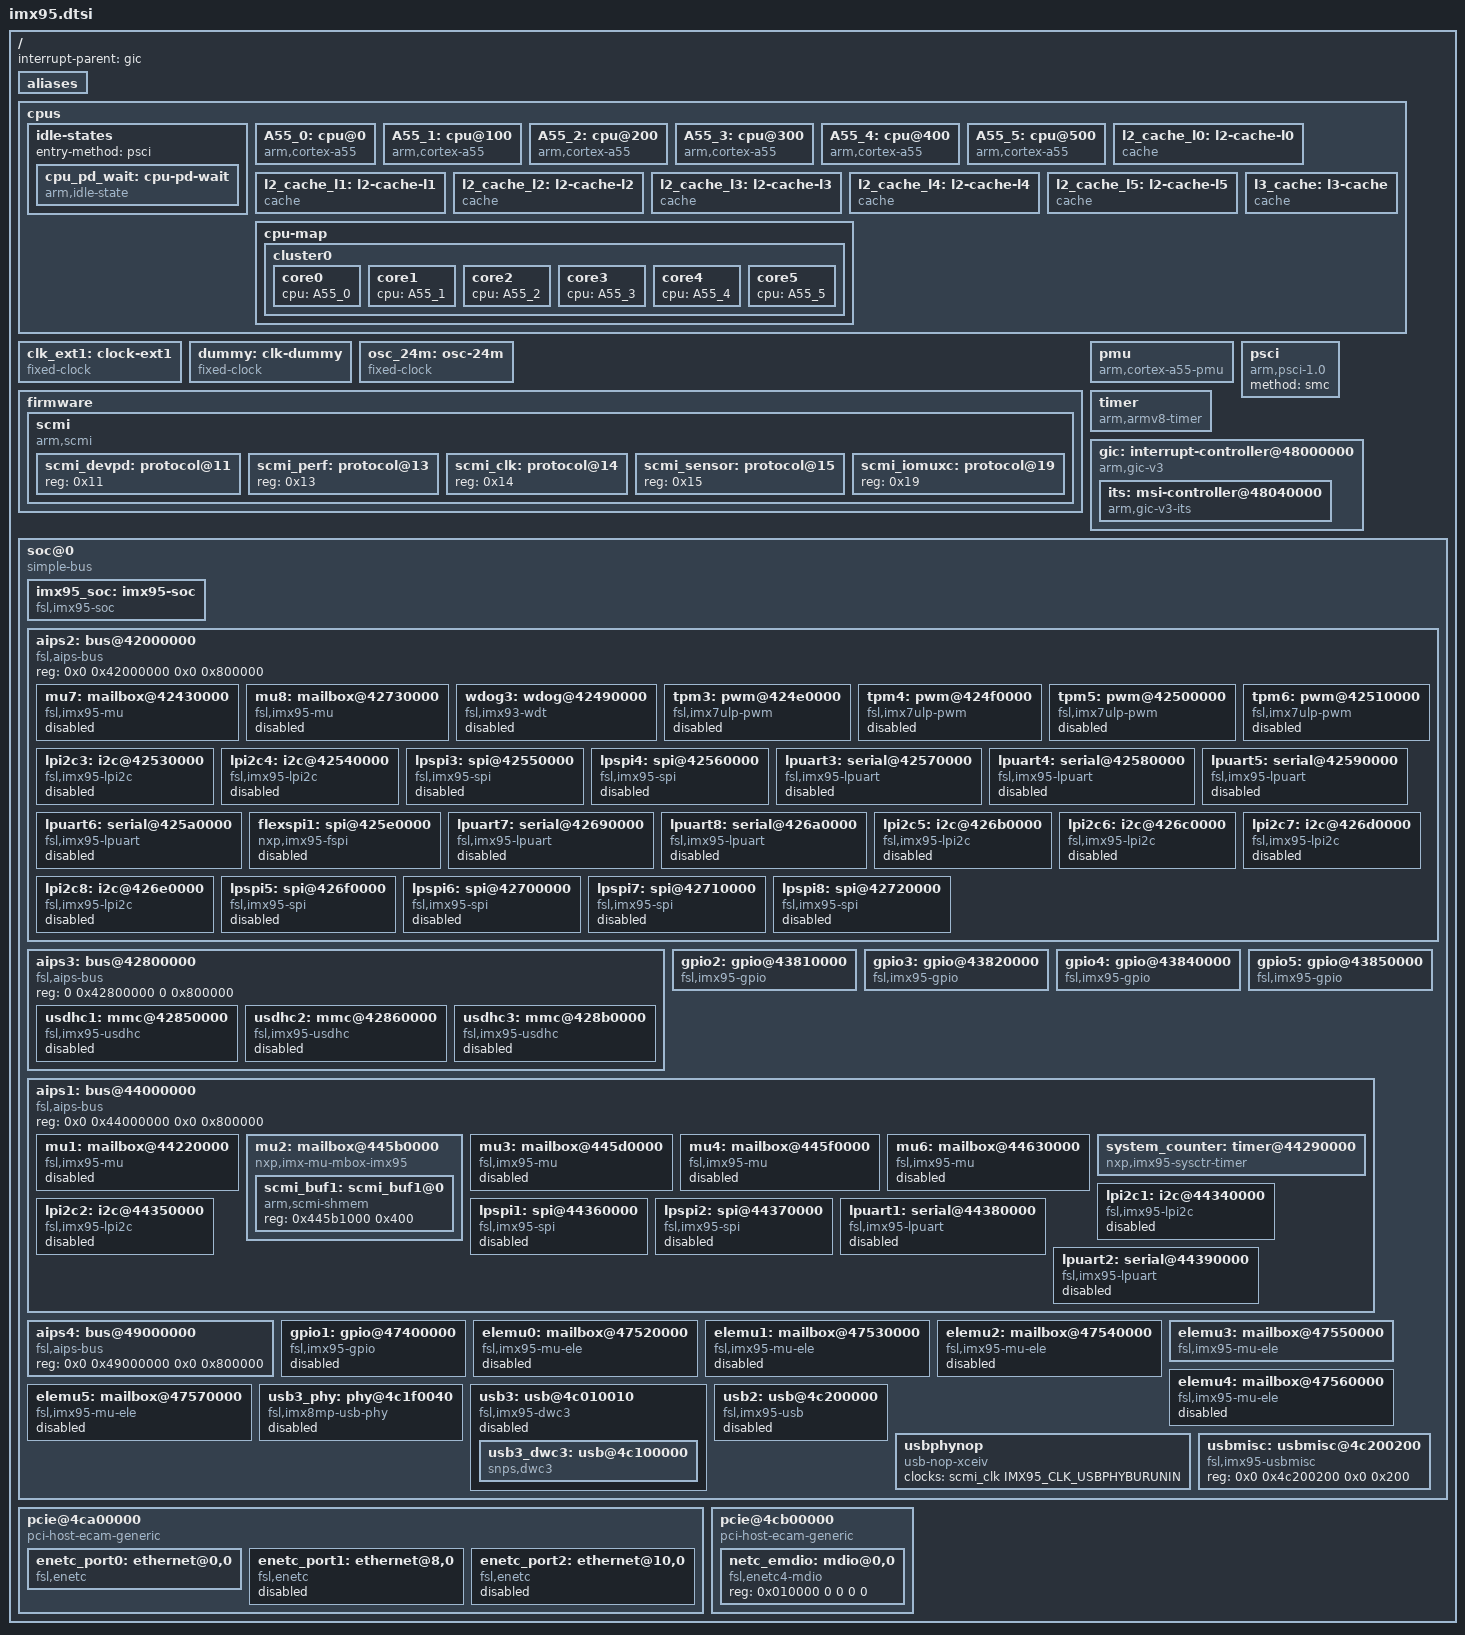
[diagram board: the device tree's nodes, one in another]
// SPDX-License-Identifier: (GPL-2.0+ OR MIT)
/*
 * Copyright 2023 NXP
 */

#include <dt-bindings/clock/fsl,imx95-clock.h>
#include <dt-bindings/gpio/gpio.h>
#include <dt-bindings/input/input.h>
#include <dt-bindings/interrupt-controller/arm-gic.h>
#include <dt-bindings/power/fsl,imx95-power.h>

#include "imx95-pinfunc.h"

/ {
	interrupt-parent = <&gic>;
	#address-cells = <2>;
	#size-cells = <2>;

	aliases {
		gpio0 = &gpio1;
		gpio1 = &gpio2;
		gpio2 = &gpio3;
		gpio3 = &gpio4;
		gpio4 = &gpio5;
		i2c0 = &lpi2c1;
		i2c1 = &lpi2c2;
		i2c2 = &lpi2c3;
		i2c3 = &lpi2c4;
		i2c4 = &lpi2c5;
		i2c5 = &lpi2c6;
		i2c6 = &lpi2c7;
		i2c7 = &lpi2c8;
		mmc0 = &usdhc1;
		mmc1 = &usdhc2;
		mmc2 = &usdhc3;
		serial0 = &lpuart1;
		serial1 = &lpuart2;
		serial2 = &lpuart3;
		serial3 = &lpuart4;
		serial4 = &lpuart5;
		serial5 = &lpuart6;
		serial6 = &lpuart7;
		serial7 = &lpuart8;
		spi0 = &flexspi1;
		usb0 = &usb3_dwc3;
		usb1 = &usb2;
	};

	cpus {
		#address-cells = <1>;
		#size-cells = <0>;

		idle-states {
			entry-method = "psci";

			cpu_pd_wait: cpu-pd-wait {
				compatible = "arm,idle-state";
				arm,psci-suspend-param = <0x0010033>;
				local-timer-stop;
				entry-latency-us = <1000>;
				exit-latency-us = <700>;
				min-residency-us = <2700>;
				wakeup-latency-us = <1500>;
			};
		};

		A55_0: cpu@0 {
			device_type = "cpu";
			compatible = "arm,cortex-a55";
			reg = <0x0>;
			enable-method = "psci";
			#cooling-cells = <2>;
			cpu-idle-states = <&cpu_pd_wait>;
			power-domains = <&scmi_devpd IMX95_PERF_A55>;
			power-domain-names = "perf";
			i-cache-size = <32768>;
			i-cache-line-size = <64>;
			i-cache-sets = <128>;
			d-cache-size = <32768>;
			d-cache-line-size = <64>;
			d-cache-sets = <128>;
			next-level-cache = <&l2_cache_l0>;
		};

		A55_1: cpu@100 {
			device_type = "cpu";
			compatible = "arm,cortex-a55";
			reg = <0x100>;
			enable-method = "psci";
			#cooling-cells = <2>;
			cpu-idle-states = <&cpu_pd_wait>;
			power-domains = <&scmi_devpd IMX95_PERF_A55>;
			power-domain-names = "perf";
			i-cache-size = <32768>;
			i-cache-line-size = <64>;
			i-cache-sets = <128>;
			d-cache-size = <32768>;
			d-cache-line-size = <64>;
			d-cache-sets = <128>;
			next-level-cache = <&l2_cache_l1>;
		};

		A55_2: cpu@200 {
			device_type = "cpu";
			compatible = "arm,cortex-a55";
			reg = <0x200>;
			enable-method = "psci";
			#cooling-cells = <2>;
			cpu-idle-states = <&cpu_pd_wait>;
			power-domains = <&scmi_devpd IMX95_PERF_A55>;
			power-domain-names = "perf";
			i-cache-size = <32768>;
			i-cache-line-size = <64>;
			i-cache-sets = <128>;
			d-cache-size = <32768>;
			d-cache-line-size = <64>;
			d-cache-sets = <128>;
			next-level-cache = <&l2_cache_l2>;
		};

		A55_3: cpu@300 {
			device_type = "cpu";
			compatible = "arm,cortex-a55";
			reg = <0x300>;
			enable-method = "psci";
			#cooling-cells = <2>;
			power-domains = <&scmi_devpd IMX95_PERF_A55>;
			power-domain-names = "perf";
			i-cache-size = <32768>;
			i-cache-line-size = <64>;
			i-cache-sets = <128>;
			d-cache-size = <32768>;
			d-cache-line-size = <64>;
			d-cache-sets = <128>;
			next-level-cache = <&l2_cache_l3>;
		};

		A55_4: cpu@400 {
			device_type = "cpu";
			compatible = "arm,cortex-a55";
			reg = <0x400>;
			power-domains = <&scmi_devpd IMX95_PERF_A55>;
			power-domain-names = "perf";
			enable-method = "psci";
			#cooling-cells = <2>;
			cpu-idle-states = <&cpu_pd_wait>;
			i-cache-size = <32768>;
			i-cache-line-size = <64>;
			i-cache-sets = <128>;
			d-cache-size = <32768>;
			d-cache-line-size = <64>;
			d-cache-sets = <128>;
			next-level-cache = <&l2_cache_l4>;
		};

		A55_5: cpu@500 {
			device_type = "cpu";
			compatible = "arm,cortex-a55";
			reg = <0x500>;
			power-domains = <&scmi_devpd IMX95_PERF_A55>;
			power-domain-names = "perf";
			enable-method = "psci";
			#cooling-cells = <2>;
			cpu-idle-states = <&cpu_pd_wait>;
			i-cache-size = <32768>;
			i-cache-line-size = <64>;
			i-cache-sets = <128>;
			d-cache-size = <32768>;
			d-cache-line-size = <64>;
			d-cache-sets = <128>;
			next-level-cache = <&l2_cache_l5>;
		};

		l2_cache_l0: l2-cache-l0 {
			compatible = "cache";
			cache-size = <65536>;
			cache-line-size = <64>;
			cache-sets = <256>;
			cache-level = <2>;
			cache-unified;
			next-level-cache = <&l3_cache>;
		};

		l2_cache_l1: l2-cache-l1 {
			compatible = "cache";
			cache-size = <65536>;
			cache-line-size = <64>;
			cache-sets = <256>;
			cache-level = <2>;
			cache-unified;
			next-level-cache = <&l3_cache>;
		};

		l2_cache_l2: l2-cache-l2 {
			compatible = "cache";
			cache-size = <65536>;
			cache-line-size = <64>;
			cache-sets = <256>;
			cache-level = <2>;
			cache-unified;
			next-level-cache = <&l3_cache>;
		};

		l2_cache_l3: l2-cache-l3 {
			compatible = "cache";
			cache-size = <65536>;
			cache-line-size = <64>;
			cache-sets = <256>;
			cache-level = <2>;
			cache-unified;
			next-level-cache = <&l3_cache>;
		};

		l2_cache_l4: l2-cache-l4 {
			compatible = "cache";
			cache-size = <65536>;
			cache-line-size = <64>;
			cache-sets = <256>;
			cache-level = <2>;
			cache-unified;
			next-level-cache = <&l3_cache>;
		};

		l2_cache_l5: l2-cache-l5 {
			compatible = "cache";
			cache-size = <65536>;
			cache-line-size = <64>;
			cache-sets = <256>;
			cache-level = <2>;
			cache-unified;
			next-level-cache = <&l3_cache>;
		};

		l3_cache: l3-cache {
			compatible = "cache";
			cache-size = <524288>;
			cache-line-size = <64>;
			cache-sets = <1024>;
			cache-level = <3>;
			cache-unified;
		};

		cpu-map {
			cluster0 {
				core0 {
					cpu = <&A55_0>;
				};

				core1 {
					cpu = <&A55_1>;
				};

				core2 {
					cpu = <&A55_2>;
				};

				core3 {
					cpu = <&A55_3>;
				};

				core4 {
					cpu = <&A55_4>;
				};

				core5 {
					cpu = <&A55_5>;
				};
			};
		};
	};

	clk_ext1: clock-ext1 {
		compatible = "fixed-clock";
		#clock-cells = <0>;
		clock-frequency = <133000000>;
		clock-output-names = "clk_ext1";
	};

	dummy: clk-dummy {
		compatible = "fixed-clock";
		#clock-cells = <0>;
		clock-frequency = <0>;
		clock-output-names = "dummy";
	};

	osc_24m: osc-24m {
		compatible = "fixed-clock";
		#clock-cells = <0>;
		clock-frequency = <24000000>;
		clock-output-names = "osc_24m";
	};

	firmware {
		scmi {
			compatible = "arm,scmi";
			mboxes = <&mu2 0>;
			shmem = <&scmi_buf1>;
			#address-cells = <1>;
			#size-cells = <0>;

			scmi_devpd: protocol@11 {
				reg = <0x11>;
				#power-domain-cells = <1>;
			};

			scmi_perf: protocol@13 {
				reg = <0x13>;
				#clock-cells = <1>;
				#power-domain-cells = <1>;
			};

			scmi_clk: protocol@14 {
				reg = <0x14>;
				#clock-cells = <1>;
			};

			scmi_sensor: protocol@15 {
				reg = <0x15>;
				#thermal-sensor-cells = <1>;
			};

			scmi_iomuxc: protocol@19 {
				reg = <0x19>;
			};
		};
	};

	pmu {
		compatible = "arm,cortex-a55-pmu";
		interrupts = <GIC_PPI 7 (GIC_CPU_MASK_SIMPLE(6) | IRQ_TYPE_LEVEL_HIGH)>;
	};

	psci {
		compatible = "arm,psci-1.0";
		method = "smc";
	};

	timer {
		compatible = "arm,armv8-timer";
		interrupts = <GIC_PPI 13 (GIC_CPU_MASK_SIMPLE(6) | IRQ_TYPE_LEVEL_LOW)>,
			     <GIC_PPI 14 (GIC_CPU_MASK_SIMPLE(6) | IRQ_TYPE_LEVEL_LOW)>,
			     <GIC_PPI 11 (GIC_CPU_MASK_SIMPLE(6) | IRQ_TYPE_LEVEL_LOW)>,
			     <GIC_PPI 10 (GIC_CPU_MASK_SIMPLE(6) | IRQ_TYPE_LEVEL_LOW)>;
		clock-frequency = <24000000>;
		arm,no-tick-in-suspend;
		interrupt-parent = <&gic>;
	};

	gic: interrupt-controller@48000000 {
		compatible = "arm,gic-v3";
		#address-cells = <2>;
		#size-cells = <2>;
		reg = <0 0x48000000 0 0x10000>,
		      <0 0x48060000 0 0xc0000>;
		#interrupt-cells = <3>;
		interrupt-controller;
		interrupts = <GIC_PPI 9 IRQ_TYPE_LEVEL_HIGH>;
		interrupt-parent = <&gic>;
		dma-noncoherent;

		ranges;

		its: msi-controller@48040000 {
			compatible = "arm,gic-v3-its";
			dma-noncoherent;
			msi-controller;
			reg = <0 0x48040000 0 0x20000>;
		};
	};


	soc@0 {
		compatible = "simple-bus";
		#address-cells = <2>;
		#size-cells = <2>;
		ranges = <0x0 0x0 0x0 0x0 0x0 0x80000000>,
			 <0x0 0x28000000 0x0 0x28000000 0x0 0x10000000>;

		imx95_soc: imx95-soc {
			compatible = "fsl,imx95-soc";
		};

		aips2: bus@42000000 {
			compatible = "fsl,aips-bus", "simple-bus";
			reg = <0x0 0x42000000 0x0 0x800000>;
			#address-cells = <1>;
			#size-cells = <1>;
			ranges = <0x42000000 0x0 0x42000000 0x8000000>,
				 <0x28000000 0x0 0x28000000 0x10000000>;

			mu7: mailbox@42430000 {
				compatible = "fsl,imx95-mu", "fsl,imx8ulp-mu";
				reg = <0x42430000 0x10000>;
				interrupts = <GIC_SPI 234 IRQ_TYPE_LEVEL_HIGH>;
				clocks = <&scmi_clk IMX95_CLK_BUSWAKEUP>;
				#mbox-cells = <2>;
				status = "disabled";
			};

			mu8: mailbox@42730000 {
				compatible = "fsl,imx95-mu", "fsl,imx8ulp-mu";
				reg = <0x42730000 0x10000>;
				interrupts = <GIC_SPI 235 IRQ_TYPE_LEVEL_HIGH>;
				clocks = <&scmi_clk IMX95_CLK_BUSWAKEUP>;
				#mbox-cells = <2>;
				status = "disabled";
			};

			wdog3: wdog@42490000 {
				compatible = "fsl,imx93-wdt";
				reg = <0x42490000 0x10000>;
				interrupts = <GIC_SPI 79 IRQ_TYPE_LEVEL_HIGH>;
				clocks = <&scmi_clk IMX95_CLK_BUSWAKEUP>;
				timeout-sec = <40>;
				status = "disabled";
			};

			tpm3: pwm@424e0000 {
				compatible = "fsl,imx7ulp-pwm";
				reg = <0x424e0000 0x1000>;
				clocks = <&scmi_clk IMX95_CLK_BUSWAKEUP>;
				#pwm-cells = <3>;
				status = "disabled";
			};

			tpm4: pwm@424f0000 {
				compatible = "fsl,imx7ulp-pwm";
				reg = <0x424f0000 0x1000>;
				clocks = <&scmi_clk IMX95_CLK_TPM4>;
				#pwm-cells = <3>;
				status = "disabled";
			};

			tpm5: pwm@42500000 {
				compatible = "fsl,imx7ulp-pwm";
				reg = <0x42500000 0x1000>;
				clocks = <&scmi_clk IMX95_CLK_TPM5>;
				#pwm-cells = <3>;
				status = "disabled";
			};

			tpm6: pwm@42510000 {
				compatible = "fsl,imx7ulp-pwm";
				reg = <0x42510000 0x1000>;
				clocks = <&scmi_clk IMX95_CLK_TPM6>;
				#pwm-cells = <3>;
				status = "disabled";
			};

			lpi2c3: i2c@42530000 {
				compatible = "fsl,imx95-lpi2c", "fsl,imx7ulp-lpi2c";
				reg = <0x42530000 0x10000>;
				interrupts = <GIC_SPI 58 IRQ_TYPE_LEVEL_HIGH>;
				clocks = <&scmi_clk IMX95_CLK_LPI2C3>,
					 <&scmi_clk IMX95_CLK_BUSWAKEUP>;
				clock-names = "per", "ipg";
				status = "disabled";
			};

			lpi2c4: i2c@42540000 {
				compatible = "fsl,imx95-lpi2c", "fsl,imx7ulp-lpi2c";
				reg = <0x42540000 0x10000>;
				interrupts = <GIC_SPI 59 IRQ_TYPE_LEVEL_HIGH>;
				clocks = <&scmi_clk IMX95_CLK_LPI2C4>,
					 <&scmi_clk IMX95_CLK_BUSWAKEUP>;
				clock-names = "per", "ipg";
				status = "disabled";
			};

			lpspi3: spi@42550000 {
				#address-cells = <1>;
				#size-cells = <0>;
				compatible = "fsl,imx95-spi", "fsl,imx7ulp-spi";
				reg = <0x42550000 0x10000>;
				interrupts = <GIC_SPI 61 IRQ_TYPE_LEVEL_HIGH>;
				clocks = <&scmi_clk IMX95_CLK_LPSPI3>,
					 <&scmi_clk IMX95_CLK_BUSWAKEUP>;
				clock-names = "per", "ipg";
				status = "disabled";
			};

			lpspi4: spi@42560000 {
				#address-cells = <1>;
				#size-cells = <0>;
				compatible = "fsl,imx95-spi", "fsl,imx7ulp-spi";
				reg = <0x42560000 0x10000>;
				interrupts = <GIC_SPI 62 IRQ_TYPE_LEVEL_HIGH>;
				clocks = <&scmi_clk IMX95_CLK_LPSPI4>,
					 <&scmi_clk IMX95_CLK_BUSWAKEUP>;
				clock-names = "per", "ipg";
				status = "disabled";
			};

			lpuart3: serial@42570000 {
				compatible = "fsl,imx95-lpuart", "fsl,imx8ulp-lpuart",
					     "fsl,imx7ulp-lpuart";
				reg = <0x42570000 0x1000>;
				interrupts = <GIC_SPI 64 IRQ_TYPE_LEVEL_HIGH>;
				clocks = <&scmi_clk IMX95_CLK_LPUART3>;
				clock-names = "ipg";
				status = "disabled";
			};

			lpuart4: serial@42580000 {
				compatible = "fsl,imx95-lpuart", "fsl,imx8ulp-lpuart",
					     "fsl,imx7ulp-lpuart";
				reg = <0x42580000 0x1000>;
				interrupts = <GIC_SPI 65 IRQ_TYPE_LEVEL_HIGH>;
				clocks = <&scmi_clk IMX95_CLK_LPUART4>;
				clock-names = "ipg";
				status = "disabled";
			};

			lpuart5: serial@42590000 {
				compatible = "fsl,imx95-lpuart", "fsl,imx8ulp-lpuart",
					     "fsl,imx7ulp-lpuart";
				reg = <0x42590000 0x1000>;
				interrupts = <GIC_SPI 66 IRQ_TYPE_LEVEL_HIGH>;
				clocks = <&scmi_clk IMX95_CLK_LPUART5>;
				clock-names = "ipg";
				status = "disabled";
			};

			lpuart6: serial@425a0000 {
				compatible = "fsl,imx95-lpuart", "fsl,imx8ulp-lpuart",
					     "fsl,imx7ulp-lpuart";
				reg = <0x425a0000 0x1000>;
				interrupts = <GIC_SPI 67 IRQ_TYPE_LEVEL_HIGH>;
				clocks = <&scmi_clk IMX95_CLK_LPUART6>;
				clock-names = "ipg";
				status = "disabled";
			};

			flexspi1: spi@425e0000 {
				#address-cells = <1>;
				#size-cells = <0>;
				compatible = "nxp,imx95-fspi", "nxp,imx8mm-fspi";
				reg = <0x425e0000 0x10000>, <0x28000000 0x8000000>;
				reg-names = "fspi_base", "fspi_mmap";
				interrupts = <GIC_SPI 48 IRQ_TYPE_LEVEL_HIGH>;
				clocks = <&scmi_clk IMX95_CLK_FLEXSPI1>,
					 <&scmi_clk IMX95_CLK_FLEXSPI1>;
				clock-names = "fspi", "fspi_en";
				assigned-clocks = <&scmi_clk IMX95_CLK_FLEXSPI1>;
				assigned-clock-parents = <&scmi_clk IMX95_CLK_SYSPLL1_PFD1>;
				assigned-clock-rates = <200000000>;
				status = "disabled";
			};

			lpuart7: serial@42690000 {
				compatible = "fsl,imx95-lpuart", "fsl,imx8ulp-lpuart",
					     "fsl,imx7ulp-lpuart";
				reg = <0x42690000 0x1000>;
				interrupts = <GIC_SPI 68 IRQ_TYPE_LEVEL_HIGH>;
				clocks = <&scmi_clk IMX95_CLK_LPUART7>;
				clock-names = "ipg";
				status = "disabled";
			};

			lpuart8: serial@426a0000 {
				compatible = "fsl,imx95-lpuart", "fsl,imx8ulp-lpuart",
					     "fsl,imx7ulp-lpuart";
				reg = <0x426a0000 0x1000>;
				interrupts = <GIC_SPI 69 IRQ_TYPE_LEVEL_HIGH>;
				clocks = <&scmi_clk IMX95_CLK_LPUART8>;
				clock-names = "ipg";
				status = "disabled";
			};

			lpi2c5: i2c@426b0000 {
				compatible = "fsl,imx95-lpi2c", "fsl,imx7ulp-lpi2c";
				reg = <0x426b0000 0x10000>;
				interrupts = <GIC_SPI 181 IRQ_TYPE_LEVEL_HIGH>;
				clocks = <&scmi_clk IMX95_CLK_LPI2C5>,
					 <&scmi_clk IMX95_CLK_BUSWAKEUP>;
				clock-names = "per", "ipg";
				status = "disabled";
			};

			lpi2c6: i2c@426c0000 {
				compatible = "fsl,imx95-lpi2c", "fsl,imx7ulp-lpi2c";
				reg = <0x426c0000 0x10000>;
				interrupts = <GIC_SPI 182 IRQ_TYPE_LEVEL_HIGH>;
				clocks = <&scmi_clk IMX95_CLK_LPI2C6>,
					 <&scmi_clk IMX95_CLK_BUSWAKEUP>;
				clock-names = "per", "ipg";
				status = "disabled";
			};

			lpi2c7: i2c@426d0000 {
				compatible = "fsl,imx95-lpi2c", "fsl,imx7ulp-lpi2c";
				reg = <0x426d0000 0x10000>;
				interrupts = <GIC_SPI 183 IRQ_TYPE_LEVEL_HIGH>;
				clocks = <&scmi_clk IMX95_CLK_LPI2C7>,
					 <&scmi_clk IMX95_CLK_BUSWAKEUP>;
				clock-names = "per", "ipg";
				status = "disabled";
			};

			lpi2c8: i2c@426e0000 {
				compatible = "fsl,imx95-lpi2c", "fsl,imx7ulp-lpi2c";
				reg = <0x426e0000 0x10000>;
				interrupts = <GIC_SPI 184 IRQ_TYPE_LEVEL_HIGH>;
				clocks = <&scmi_clk IMX95_CLK_LPI2C8>,
					 <&scmi_clk IMX95_CLK_BUSWAKEUP>;
				clock-names = "per", "ipg";
				status = "disabled";
			};

			lpspi5: spi@426f0000 {
				#address-cells = <1>;
				#size-cells = <0>;
				compatible = "fsl,imx95-spi", "fsl,imx7ulp-spi";
				reg = <0x426f0000 0x10000>;
				interrupts = <GIC_SPI 177 IRQ_TYPE_LEVEL_HIGH>;
				clocks = <&scmi_clk IMX95_CLK_LPSPI5>,
					 <&scmi_clk IMX95_CLK_BUSWAKEUP>;
				clock-names = "per", "ipg";
				status = "disabled";
			};

			lpspi6: spi@42700000 {
				#address-cells = <1>;
				#size-cells = <0>;
				compatible = "fsl,imx95-spi", "fsl,imx7ulp-spi";
				reg = <0x42700000 0x10000>;
				interrupts = <GIC_SPI 178 IRQ_TYPE_LEVEL_HIGH>;
				clocks = <&scmi_clk IMX95_CLK_LPSPI6>,
					 <&scmi_clk IMX95_CLK_BUSWAKEUP>;
				clock-names = "per", "ipg";
				status = "disabled";
			};

			lpspi7: spi@42710000 {
				#address-cells = <1>;
				#size-cells = <0>;
				compatible = "fsl,imx95-spi", "fsl,imx7ulp-spi";
				reg = <0x42710000 0x10000>;
				interrupts = <GIC_SPI 179 IRQ_TYPE_LEVEL_HIGH>;
				clocks = <&scmi_clk IMX95_CLK_LPSPI7>,
					 <&scmi_clk IMX95_CLK_BUSWAKEUP>;
				clock-names = "per", "ipg";
				status = "disabled";
			};

			lpspi8: spi@42720000 {
				#address-cells = <1>;
				#size-cells = <0>;
				compatible = "fsl,imx95-spi", "fsl,imx7ulp-spi";
				reg = <0x42720000 0x10000>;
				interrupts = <GIC_SPI 180 IRQ_TYPE_LEVEL_HIGH>;
				clocks = <&scmi_clk IMX95_CLK_LPSPI8>,
					 <&scmi_clk IMX95_CLK_BUSWAKEUP>;
				clock-names = "per", "ipg";
				status = "disabled";
			};
		};

		aips3: bus@42800000 {
			compatible = "fsl,aips-bus", "simple-bus";
			reg = <0 0x42800000 0 0x800000>;
			#address-cells = <1>;
			#size-cells = <1>;
			ranges = <0x42800000 0x0 0x42800000 0x800000>;

			usdhc1: mmc@42850000 {
				compatible = "fsl,imx95-usdhc", "fsl,imx8mm-usdhc";
				reg = <0x42850000 0x10000>;
				interrupts = <GIC_SPI 86 IRQ_TYPE_LEVEL_HIGH>;
				clocks = <&scmi_clk IMX95_CLK_BUSWAKEUP>,
					 <&scmi_clk IMX95_CLK_WAKEUPAXI>,
					 <&scmi_clk IMX95_CLK_USDHC1>;
				clock-names = "ipg", "ahb", "per";
				assigned-clocks = <&scmi_clk IMX95_CLK_USDHC1>;
				assigned-clock-parents = <&scmi_clk IMX95_CLK_SYSPLL1_PFD1>;
				assigned-clock-rates = <400000000>;
				bus-width = <8>;
				fsl,tuning-start-tap = <1>;
				fsl,tuning-step= <2>;
				status = "disabled";
			};

			usdhc2: mmc@42860000 {
				compatible = "fsl,imx95-usdhc", "fsl,imx8mm-usdhc";
				reg = <0x42860000 0x10000>;
				interrupts = <GIC_SPI 87 IRQ_TYPE_LEVEL_HIGH>;
				clocks = <&scmi_clk IMX95_CLK_BUSWAKEUP>,
					 <&scmi_clk IMX95_CLK_WAKEUPAXI>,
					 <&scmi_clk IMX95_CLK_USDHC2>;
				clock-names = "ipg", "ahb", "per";
				assigned-clocks = <&scmi_clk IMX95_CLK_USDHC2>;
				assigned-clock-parents = <&scmi_clk IMX95_CLK_SYSPLL1_PFD1>;
				assigned-clock-rates = <200000000>;
				bus-width = <4>;
				fsl,tuning-start-tap = <1>;
				fsl,tuning-step= <2>;
				status = "disabled";
			};

			usdhc3: mmc@428b0000 {
				compatible = "fsl,imx95-usdhc", "fsl,imx8mm-usdhc";
				reg = <0x428b0000 0x10000>;
				interrupts = <GIC_SPI 191 IRQ_TYPE_LEVEL_HIGH>;
				clocks = <&scmi_clk IMX95_CLK_BUSWAKEUP>,
					 <&scmi_clk IMX95_CLK_WAKEUPAXI>,
					 <&scmi_clk IMX95_CLK_USDHC3>;
				clock-names = "ipg", "ahb", "per";
				bus-width = <4>;
				fsl,tuning-start-tap = <1>;
				fsl,tuning-step= <2>;
				status = "disabled";
			};
		};

		gpio2: gpio@43810000 {
			compatible = "fsl,imx95-gpio", "fsl,imx8ulp-gpio";
			reg = <0x0 0x43810000 0x0 0x1000>;
			gpio-controller;
			#gpio-cells = <2>;
			interrupts = <GIC_SPI 49 IRQ_TYPE_LEVEL_HIGH>,
				     <GIC_SPI 50 IRQ_TYPE_LEVEL_HIGH>;
			interrupt-controller;
			#interrupt-cells = <2>;
			clocks = <&scmi_clk IMX95_CLK_BUSWAKEUP>,
				 <&scmi_clk IMX95_CLK_BUSWAKEUP>;
			clock-names = "gpio", "port";
			gpio-ranges = <&scmi_iomuxc 0 4 32>;
		};

		gpio3: gpio@43820000 {
			compatible = "fsl,imx95-gpio", "fsl,imx8ulp-gpio";
			reg = <0x0 0x43820000 0x0 0x1000>;
			gpio-controller;
			#gpio-cells = <2>;
			interrupts = <GIC_SPI 51 IRQ_TYPE_LEVEL_HIGH>,
				     <GIC_SPI 52 IRQ_TYPE_LEVEL_HIGH>;
			interrupt-controller;
			#interrupt-cells = <2>;
			clocks = <&scmi_clk IMX95_CLK_BUSWAKEUP>,
				 <&scmi_clk IMX95_CLK_BUSWAKEUP>;
			clock-names = "gpio", "port";
			gpio-ranges = <&scmi_iomuxc 0 104 8>, <&scmi_iomuxc 8 74 18>,
				      <&scmi_iomuxc 26 42 2>, <&scmi_iomuxc 28 0 4>;
		};

		gpio4: gpio@43840000 {
			compatible = "fsl,imx95-gpio", "fsl,imx8ulp-gpio";
			reg = <0x0 0x43840000 0x0 0x1000>;
			gpio-controller;
			#gpio-cells = <2>;
			interrupts = <GIC_SPI 53 IRQ_TYPE_LEVEL_HIGH>,
				     <GIC_SPI 54 IRQ_TYPE_LEVEL_HIGH>;
			interrupt-controller;
			#interrupt-cells = <2>;
			clocks = <&scmi_clk IMX95_CLK_BUSWAKEUP>,
				 <&scmi_clk IMX95_CLK_BUSWAKEUP>;
			clock-names = "gpio", "port";
			gpio-ranges = <&scmi_iomuxc 0 46 28>, <&scmi_iomuxc 28 44 2>;
		};

		gpio5: gpio@43850000 {
			compatible = "fsl,imx95-gpio", "fsl,imx8ulp-gpio";
			reg = <0x0 0x43850000 0x0 0x1000>;
			gpio-controller;
			#gpio-cells = <2>;
			interrupts = <GIC_SPI 55 IRQ_TYPE_LEVEL_HIGH>,
				     <GIC_SPI 56 IRQ_TYPE_LEVEL_HIGH>;
			interrupt-controller;
			#interrupt-cells = <2>;
			clocks = <&scmi_clk IMX95_CLK_BUSWAKEUP>,
				 <&scmi_clk IMX95_CLK_BUSWAKEUP>;
			clock-names = "gpio", "port";
			gpio-ranges = <&scmi_iomuxc 0 92 12>, <&scmi_iomuxc 12 36 6>;
		};

		aips1: bus@44000000 {
			compatible = "fsl,aips-bus", "simple-bus";
			reg = <0x0 0x44000000 0x0 0x800000>;
			#address-cells = <1>;
			#size-cells = <1>;
			ranges = <0x44000000 0x0 0x44000000 0x800000>;

			mu1: mailbox@44220000 {
				compatible = "fsl,imx95-mu", "fsl,imx8ulp-mu";
				reg = <0x44220000 0x10000>;
				interrupts = <GIC_SPI 224 IRQ_TYPE_LEVEL_HIGH>;
				clocks = <&scmi_clk IMX95_CLK_BUSAON>;
				#mbox-cells = <2>;
				status = "disabled";
			};

			mu2: mailbox@445b0000 {
				compatible = "nxp,imx-mu-mbox-imx95", "fsl,imx8ulp-mu";
				reg = <0x445b0000 0x10000>;
				interrupts = <GIC_SPI 226 IRQ_TYPE_LEVEL_HIGH>;
				#address-cells = <1>;
				#size-cells = <1>;
				#mbox-cells = <1>;
				status = "okay";

				scmi_buf1: scmi_buf1@0 {
					compatible = "arm,scmi-shmem";
					reg = <0x445b1000 0x400>;
				};
			};

			mu3: mailbox@445d0000 {
				compatible = "fsl,imx95-mu", "fsl,imx8ulp-mu";
				reg = <0x445d0000 0x10000>;
				interrupts = <GIC_SPI 228 IRQ_TYPE_LEVEL_HIGH>;
				clocks = <&scmi_clk IMX95_CLK_BUSAON>;
				#mbox-cells = <2>;
				status = "disabled";
			};

			mu4: mailbox@445f0000 {
				compatible = "fsl,imx95-mu", "fsl,imx8ulp-mu";
				reg = <0x445f0000 0x10000>;
				interrupts = <GIC_SPI 230 IRQ_TYPE_LEVEL_HIGH>;
				clocks = <&scmi_clk IMX95_CLK_BUSAON>;
				#mbox-cells = <2>;
				status = "disabled";
			};

			mu6: mailbox@44630000 {
				compatible = "fsl,imx95-mu", "fsl,imx8ulp-mu";
				reg = <0x44630000 0x10000>;
				interrupts = <GIC_SPI 206 IRQ_TYPE_LEVEL_HIGH>;
				clocks = <&scmi_clk IMX95_CLK_BUSAON>;
				#mbox-cells = <2>;
				status = "disabled";
			};

			system_counter: timer@44290000 {
				compatible = "nxp,imx95-sysctr-timer", "nxp,sysctr-timer";
				reg = <0x44290000 0x30000>;
				interrupts = <GIC_SPI 72 IRQ_TYPE_LEVEL_HIGH>;
				clocks = <&osc_24m>;
				clock-names = "per";
				nxp,no-divider;
			};

			lpi2c1: i2c@44340000 {
				compatible = "fsl,imx95-lpi2c", "fsl,imx7ulp-lpi2c";
				reg = <0x44340000 0x10000>;
				interrupts = <GIC_SPI 13 IRQ_TYPE_LEVEL_HIGH>;
				clocks = <&scmi_clk IMX95_CLK_LPI2C1>,
					 <&scmi_clk IMX95_CLK_BUSAON>;
				clock-names = "per", "ipg";
				status = "disabled";
			};

			lpi2c2: i2c@44350000 {
				compatible = "fsl,imx95-lpi2c", "fsl,imx7ulp-lpi2c";
				reg = <0x44350000 0x10000>;
				interrupts = <GIC_SPI 14 IRQ_TYPE_LEVEL_HIGH>;
				clocks = <&scmi_clk IMX95_CLK_LPI2C2>,
					 <&scmi_clk IMX95_CLK_BUSAON>;
				clock-names = "per", "ipg";
				status = "disabled";
			};

			lpspi1: spi@44360000 {
				#address-cells = <1>;
				#size-cells = <0>;
				compatible = "fsl,imx95-spi", "fsl,imx7ulp-spi";
				reg = <0x44360000 0x10000>;
				interrupts = <GIC_SPI 16 IRQ_TYPE_LEVEL_HIGH>;
				clocks = <&scmi_clk IMX95_CLK_LPSPI1>,
					 <&scmi_clk IMX95_CLK_BUSAON>;
				clock-names = "per", "ipg";
				status = "disabled";
			};

			lpspi2: spi@44370000 {
				#address-cells = <1>;
				#size-cells = <0>;
				compatible = "fsl,imx95-spi", "fsl,imx7ulp-spi";
				reg = <0x44370000 0x10000>;
				interrupts = <GIC_SPI 17 IRQ_TYPE_LEVEL_HIGH>;
				clocks = <&scmi_clk IMX95_CLK_LPSPI2>,
					 <&scmi_clk IMX95_CLK_BUSAON>;
				clock-names = "per", "ipg";
				status = "disabled";
			};

			lpuart1: serial@44380000 {
				compatible = "fsl,imx95-lpuart", "fsl,imx8ulp-lpuart",
					     "fsl,imx7ulp-lpuart";
				reg = <0x44380000 0x1000>;
				interrupts = <GIC_SPI 19 IRQ_TYPE_LEVEL_HIGH>;
				clocks = <&scmi_clk IMX95_CLK_LPUART1>;
				clock-names = "ipg";
				status = "disabled";
			};

			lpuart2: serial@44390000 {
				compatible = "fsl,imx95-lpuart", "fsl,imx8ulp-lpuart",
					     "fsl,imx7ulp-lpuart";
				reg = <0x44390000 0x1000>;
				interrupts = <GIC_SPI 20 IRQ_TYPE_LEVEL_HIGH>;
				clocks = <&scmi_clk IMX95_CLK_LPUART2>;
				clock-names = "ipg";
				status = "disabled";
			};

		};

		aips4: bus@49000000 {
			compatible = "fsl,aips-bus", "simple-bus";
			reg = <0x0 0x49000000 0x0 0x800000>;
			#address-cells = <1>;
			#size-cells = <1>;
			ranges = <0x49000000 0x0 0x49000000 0x800000>;
		};

		gpio1: gpio@47400000 {
			compatible = "fsl,imx95-gpio", "fsl,imx8ulp-gpio";
			reg = <0x0 0x47400000 0x0 0x1000>;
			gpio-controller;
			#gpio-cells = <2>;
			interrupts = <GIC_SPI 10 IRQ_TYPE_LEVEL_HIGH>,
				     <GIC_SPI 11 IRQ_TYPE_LEVEL_HIGH>;
			interrupt-controller;
			#interrupt-cells = <2>;
			clocks = <&scmi_clk IMX95_CLK_M33>,
				 <&scmi_clk IMX95_CLK_M33>;
			clock-names = "gpio", "port";
			gpio-ranges = <&scmi_iomuxc 0 112 16>;
			status = "disabled";
		};

		elemu0: mailbox@47520000 {
			compatible = "fsl,imx95-mu-ele";
			reg = <0x0 0x47520000 0x0 0x10000>;
			interrupts = <GIC_SPI 21 IRQ_TYPE_LEVEL_HIGH>;
			#mbox-cells = <2>;
			status = "disabled";
		};

		elemu1: mailbox@47530000 {
			compatible = "fsl,imx95-mu-ele";
			reg = <0x0 0x47530000 0x0 0x10000>;
			interrupts = <GIC_SPI 22 IRQ_TYPE_LEVEL_HIGH>;
			#mbox-cells = <2>;
			status = "disabled";
		};

		elemu2: mailbox@47540000 {
			compatible = "fsl,imx95-mu-ele";
			reg = <0x0 0x47540000 0x0 0x10000>;
			interrupts = <GIC_SPI 23 IRQ_TYPE_LEVEL_HIGH>;
			#mbox-cells = <2>;
			status = "disabled";
		};

		elemu3: mailbox@47550000 {
			compatible = "fsl,imx95-mu-ele";
			reg = <0x0 0x47550000 0x0 0x10000>;
			interrupts = <GIC_SPI 24 IRQ_TYPE_LEVEL_HIGH>;
			#mbox-cells = <2>;
		};

		elemu4: mailbox@47560000 {
			compatible = "fsl,imx95-mu-ele";
			reg = <0x0 0x47560000 0x0 0x10000>;
			interrupts = <GIC_SPI 25 IRQ_TYPE_LEVEL_HIGH>;
			#mbox-cells = <2>;
			status = "disabled";
		};

		elemu5: mailbox@47570000 {
			compatible = "fsl,imx95-mu-ele";
			reg = <0x0 0x47570000 0x0 0x10000>;
			interrupts = <GIC_SPI 26 IRQ_TYPE_LEVEL_HIGH>;
			#mbox-cells = <2>;
			status = "disabled";
		};

		usb3_phy: phy@4c1f0040 {
			compatible = "fsl,imx8mp-usb-phy";
			reg = <0x0 0x4c1f0040 0x0 0x40>;
			clocks = <&scmi_clk IMX95_CLK_HSIO>;
			clock-names = "phy";
			#phy-cells = <0>;
			status = "disabled";
		};

		usb3: usb@4c010010 {
			compatible = "fsl,imx95-dwc3", "fsl,imx8mp-dwc3";
			reg = <0x0 0x4c010010 0x0 0x04>,
			      <0x0 0x4c1f0000 0x0 0x20>;
			clocks = <&scmi_clk IMX95_CLK_HSIO>,
				 <&scmi_clk IMX95_CLK_32K>;
			clock-names = "hsio", "suspend";
			interrupts = <GIC_SPI 173 IRQ_TYPE_LEVEL_HIGH>;
			#address-cells = <2>;
			#size-cells = <2>;
			ranges;
			power-domains = <&scmi_devpd IMX95_PD_HSIO_TOP>;
			status = "disabled";

			usb3_dwc3: usb@4c100000 {
				compatible = "snps,dwc3";
				reg = <0x0 0x4c100000 0x0 0x10000>;
				clocks = <&scmi_clk IMX95_CLK_HSIO>,
					 <&scmi_clk IMX95_CLK_24M>,
					 <&scmi_clk IMX95_CLK_32K>;
				clock-names = "bus_early", "ref", "suspend";
				interrupts = <GIC_SPI 175 IRQ_TYPE_LEVEL_HIGH>;
				phys = <&usb3_phy>, <&usb3_phy>;
				phy-names = "usb2-phy", "usb3-phy";
				snps,gfladj-refclk-lpm-sel-quirk;
				snps,parkmode-disable-ss-quirk;
			};
		};

		usb2: usb@4c200000 {
			compatible = "fsl,imx95-usb";
			reg = <0x0 0x4c200000 0x0 0x200>, <0x0 0x4c010000 0x0 0x30>;
			interrupts = <GIC_SPI 176 IRQ_TYPE_LEVEL_HIGH>,
				     <GIC_SPI 174 IRQ_TYPE_LEVEL_HIGH>;
			clocks = <&scmi_clk IMX95_CLK_HSIO>;
			clock-names = "usb1_ctrl_root_clk";
			power-domains = <&scmi_devpd IMX95_PD_HSIO_TOP>;
			phys = <&usbphynop>;
			fsl,usbmisc = <&usbmisc 0>;
			status = "disabled";
		};

		usbphynop: usbphynop {
			compatible = "usb-nop-xceiv";
			#phy-cells = <0>;
			clocks = <&scmi_clk IMX95_CLK_USBPHYBURUNIN>;
			clock-names = "main_clk";
		};

		usbmisc: usbmisc@4c200200 {
			compatible = "fsl,imx95-usbmisc";
			#index-cells = <1>;
			reg = <0x0 0x4c200200 0x0 0x200>;
		};
	};

	pcie@4ca00000 {
		compatible = "pci-host-ecam-generic";
		status = "okay";
		reg = <0x0 0x4ca00000 0x0 0x100000>; /* ENETC0_PCI_HDR_TYPE0: 0x4CA00000 */
						     /* size: 2MB */
		#address-cells = <3>;
		#size-cells = <2>;
		device_type = "pci";
		bus-range = <0x0 0x0>;

		/* Table NETC Device Memory Map Layout */
		ranges = <0x82000000 0x0 0x4cc00000 0x0 0x4cc00000 0x0 0xe0000
			  0xc2000000 0x0 0x4cd00000 0x0 0x4cd00000 0x0 0x10000
			  0x82000000 0x0 0x4cd20000 0x0 0x4cd20000 0x0 0x60000
			  0xc2000000 0x0 0x4cd80000 0x0 0x4cd80000 0x0 0x60000>;

		enetc_port0: ethernet@0,0 {
			compatible = "fsl,enetc";
			reg = <0x000000 0 0 0 0>;
			clocks = <&scmi_clk IMX95_CLK_ENET>,
				 <&scmi_clk IMX95_CLK_ENETREF>;
			clock-names = "ipg_clk", "enet_ref_clk";
			status = "okay";
		};

		enetc_port1: ethernet@8,0 {
			compatible = "fsl,enetc";
			reg = <0x004000 0 0 0 0>;
			clocks = <&scmi_clk IMX95_CLK_ENET>,
				 <&scmi_clk IMX95_CLK_ENETREF>;
			clock-names = "ipg_clk", "enet_ref_clk";
			status = "disabled";
		};

		enetc_port2: ethernet@10,0 {
			compatible = "fsl,enetc";
			reg = <0x008000 0 0 0 0>;
			clocks = <&scmi_clk IMX95_CLK_ENET>,
				 <&scmi_clk IMX95_CLK_ENETREF>;
			clock-names = "ipg_clk", "enet_ref_clk";
			status = "disabled";
		};
	};

	pcie@4cb00000 {
		compatible = "pci-host-ecam-generic";
		status = "okay";
		reg = <0x0 0x4cb00000 0x0 0x100000>; /* EMDIO0_PCI_HDR_TYPE0: 0x4CB00000 */
		#address-cells = <3>;
		#size-cells = <2>;
		device_type = "pci";
		bus-range = <0x1 0x1>;

		ranges = <0x82000000 0x0 0x4cce0000 0x0 0x4cce0000 0x0 0x20000
			  0xc2000000 0x0 0x4cd10000 0x0 0x4cd10000 0x0 0x10000>;

		netc_emdio: mdio@0,0 {
			compatible = "fsl,enetc4-mdio";
			reg = <0x010000 0 0 0 0>;
			#address-cells = <1>;
			#size-cells = <0>;
			status = "okay";
		};
	};
};
